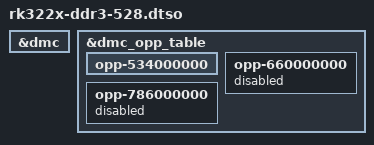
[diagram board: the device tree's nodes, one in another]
/dts-v1/;
/plugin/;

/ {

	fragment@0 {
		target = <&dmc>;
		__overlay__ {
			status = "okay";
		};
	};

	fragment@1 {
		target = <&dmc_opp_table>;
		__overlay__ {
			opp-534000000 {
				status = "okay";
			};
			opp-660000000 {
				status = "disabled";
			};
			opp-786000000 {
				status = "disabled";
			};
		};
	};

};
